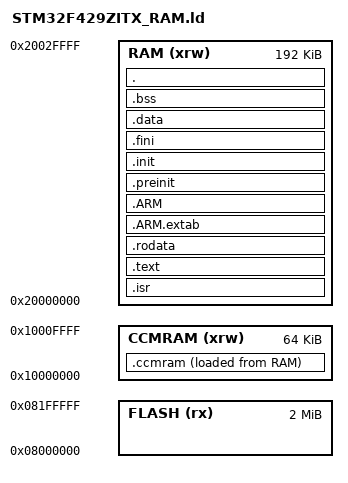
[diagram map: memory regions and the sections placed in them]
/*
<b><b><b><b><b><b><b><b><b><b><b><b><b><b><b><b><b><b><b><b><b><b><b><b><b><b><b><b><b><b><b><b><b><b><b><b><b><b><b>
<b>
<b> @file        : LinkerScript.ld (debug in RAM dedicated)
<b>
<b> @author      : Auto-generated by STM32CubeIDE
<b>
<b>  Abstract    : Linker script for NUCLEO-F429ZI Board embedding STM32F429ZITx Device from stm32f4 series
<b>                      2048Kbytes FLASH
<b>                      64Kbytes CCMRAM
<b>                      192Kbytes RAM
<b>
<b>                Set heap size, stack size and stack location according
<b>                to application requirements.
<b>
<b>                Set memory bank area and size if external memory is used
<b>
<b>  Target      : STMicroelectronics STM32
<b>
<b>  Distribution: The file is distributed as is, without any warranty
<b>                of any kind.
<b>
<b><b><b><b><b><b><b><b><b><b><b><b><b><b><b><b><b><b><b><b><b><b><b><b><b><b><b><b><b><b><b><b><b><b><b><b><b><b><b>
<b> @attention
<b>
<b> Copyright (c) 2022 STMicroelectronics.
<b> All rights reserved.
<b>
<b> This software is licensed under terms that can be found in the LICENSE file
<b> in the root directory of this software component.
<b> If no LICENSE file comes with this software, it is provided AS-IS.
<b>
<b><b><b><b><b><b><b><b><b><b><b><b><b><b><b><b><b><b><b><b><b><b><b><b><b><b><b><b><b><b><b><b><b><b><b><b><b><b><b>
*/

/* Entry Point */
ENTRY(Reset<em>Handler)

/* Highest address of the user mode stack */
<em>estack = ORIGIN(RAM) + LENGTH(RAM); /* end of "RAM" Ram type memory */

<em>Min<em>Heap<em>Size = 0x200; /* required amount of heap */
<em>Min<em>Stack<em>Size = 0x400; /* required amount of stack */

/* Memories definition */
MEMORY
{
  CCMRAM    (xrw)    : ORIGIN = 0x10000000,   LENGTH = 64K
  RAM    (xrw)    : ORIGIN = 0x20000000,   LENGTH = 192K
  FLASH    (rx)    : ORIGIN = 0x8000000,   LENGTH = 2048K
}

/* Sections */
SECTIONS
{
  /* The startup code into "RAM" Ram type memory */
  .isr<em>vector :
  {
    . = ALIGN(4);
    KEEP(*(.isr<em>vector)) /* Startup code */
    . = ALIGN(4);
  } >RAM

  /* The program code and other data into "RAM" Ram type memory */
  .text :
  {
    . = ALIGN(4);
    *(.text)           /* .text sections (code) */
    *(.text*)          /* .text* sections (code) */
    *(.glue<em>7)         /* glue arm to thumb code */
    *(.glue<em>7t)        /* glue thumb to arm code */
    *(.eh<em>frame)
    *(.RamFunc)        /* .RamFunc sections */
    *(.RamFunc*)       /* .RamFunc* sections */

    KEEP (*(.init))
    KEEP (*(.fini))

    . = ALIGN(4);
    <em>etext = .;        /* define a global symbols at end of code */
  } >RAM

  /* Constant data into "RAM" Ram type memory */
  .rodata :
  {
    . = ALIGN(4);
    *(.rodata)         /* .rodata sections (constants, strings, etc.) */
    *(.rodata*)        /* .rodata* sections (constants, strings, etc.) */
    . = ALIGN(4);
  } >RAM

  .ARM.extab   : {
    . = ALIGN(4);
    *(.ARM.extab* .gnu.linkonce.armextab.*)
    . = ALIGN(4);
  } >RAM

  .ARM : {
    . = ALIGN(4);
    <em><em>exidx<em>start = .;
    *(.ARM.exidx*)
    <em><em>exidx<em>end = .;
    . = ALIGN(4);
  } >RAM

  .preinit<em>array     :
  {
    . = ALIGN(4);
    PROVIDE<em>HIDDEN (<em><em>preinit<em>array<em>start = .);
    KEEP (*(.preinit<em>array*))
    PROVIDE<em>HIDDEN (<em><em>preinit<em>array<em>end = .);
    . = ALIGN(4);
  } >RAM

  .init<em>array :
  {
    . = ALIGN(4);
    PROVIDE<em>HIDDEN (<em><em>init<em>array<em>start = .);
    KEEP (*(SORT(.init<em>array.*)))
    KEEP (*(.init<em>array*))
    PROVIDE<em>HIDDEN (<em><em>init<em>array<em>end = .);
    . = ALIGN(4);
  } >RAM

  .fini<em>array :
  {
    . = ALIGN(4);
    PROVIDE<em>HIDDEN (<em><em>fini<em>array<em>start = .);
    KEEP (*(SORT(.fini<em>array.*)))
    KEEP (*(.fini<em>array*))
    PROVIDE<em>HIDDEN (<em><em>fini<em>array<em>end = .);
    . = ALIGN(4);
  } >RAM

  /* Used by the startup to initialize data */
  <em>sidata = LOADADDR(.data);

  /* Initialized data sections into "RAM" Ram type memory */
  .data :
  {
    . = ALIGN(4);
    <em>sdata = .;        /* create a global symbol at data start */
    *(.data)           /* .data sections */
    *(.data*)          /* .data* sections */

    . = ALIGN(4);
    <em>edata = .;        /* define a global symbol at data end */

  } >RAM

  <em>siccmram = LOADADDR(.ccmram);

  /* CCM-RAM section
  *
  * IMPORTANT NOTE!
  * If initialized variables will be placed in this section,
  * the startup code needs to be modified to copy the init-values.
  */
  .ccmram :
  {
    . = ALIGN(4);
    <em>sccmram = .;       /* create a global symbol at ccmram start */
    *(.ccmram)
    *(.ccmram*)

    . = ALIGN(4);
    <em>eccmram = .;       /* create a global symbol at ccmram end */
  } >CCMRAM AT> RAM

  /* Uninitialized data section into "RAM" Ram type memory */
  . = ALIGN(4);
  .bss :
  {
    /* This is used by the startup in order to initialize the .bss section */
    <em>sbss = .;         /* define a global symbol at bss start */
    <em><em>bss<em>start<em><em> = <em>sbss;
    *(.bss)
    *(.bss*)
    *(COMMON)

    . = ALIGN(4);
    <em>ebss = .;         /* define a global symbol at bss end */
    <em><em>bss<em>end<em><em> = <em>ebss;
  } >RAM

  /* User<em>heap<em>stack section, used to check that there is enough "RAM" Ram  type memory left */
  .<em>user<em>heap<em>stack :
  {
    . = ALIGN(8);
    PROVIDE ( end = . );
    PROVIDE ( <em>end = . );
    . = . + <em>Min<em>Heap<em>Size;
    . = . + <em>Min<em>Stack<em>Size;
    . = ALIGN(8);
  } >RAM

  /* Remove information from the compiler libraries */
  /DISCARD/ :
  {
    libc.a ( * )
    libm.a ( * )
    libgcc.a ( * )
  }

  .ARM.attributes 0 : { *(.ARM.attributes) }
}
